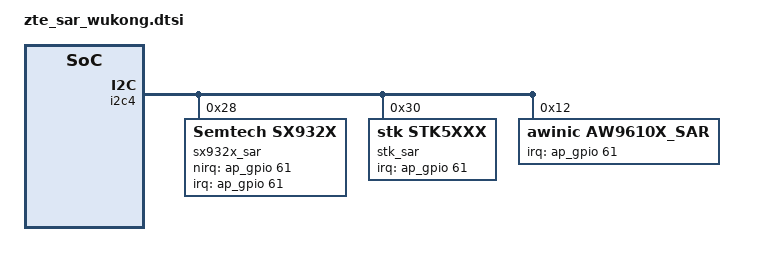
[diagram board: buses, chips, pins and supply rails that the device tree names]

&i2c4 {
	status = "okay";
	sx932x_sar:sar@28 {
		compatible = "Semtech,sx932x";
		reg = <0x28>;
		interrupt-parent = <&ap_gpio>;
		interrupts = <61 0>;
		Semtech,nirq-gpio = <&ap_gpio 61 0>;
		status ="ok";
		Semtech,reg-num = <53>;
		Semtech,reg-init  = /bits/ 8 < 0x03 0x0f /*use for compensation*/
			0x05 0x60 /*irq config*/
			0x06 0x00
			0x07 0x80
			0x08 0x00
			0x10 0x16
			0x14 0x00
			0x15 0x00
			0x20 0x10 /**/
			0x21 0x10
			0x22 0x00
			0x23 0x01
			0x24 0x17
			0x25 0x00
			0x26 0x01
			0x27 0x17
			0x28 0x3D /*PH0: CS config CS2-GND,CS1-HZ,CS0-HZ */
			0x29 0x34 /*PH1: CS config CS2-GND,CS1-input,CS0-GND*/
			0x2A 0x1F /*PH2: CS config CS2-input,CS1-GND,CS0-GND*/
			0x2B 0x37 /*PH3: CS config CS2-GND,CS1-input,CS0-GND*/
			0x2C 0x12 /**/
			0x2D 0x06
			0x30 0x0A
			0x31 0x08
			0x32 0x20
			0x33 0x20
			0x34 0x0B
			0x35 0x1A
			0x36 0x20 /*PH0/1 threshold*/
			0x37 0x24 /*PH2/3 threshold*/
			0x40 0x00
			0x41 0x00
			0x42 0x00
			0x43 0x00
			0x44 0x00
			0x45 0x05
			0x46 0x00
			0x47 0x00
			0x48 0x00
			0x49 0x00
			0x4A 0x40
			0x4B 0x00
			0x4C 0x00
			0x4D 0x00
			0x4E 0x80
			0x4F 0x0C
			0x50 0x00
			0x51 0x00
			0x52 0x00
			0x53 0x00
			0x54 0x00
			0x60 0x01
			0x11 0x22>; /*PH select PH1*/
	};
	stk_sar:stk@30 {
		compatible = "stk,stk5xxx";
		reg = <0x30>;
		interrupt-parent = <&ap_gpio>;
		stk5xxx,irq-gpio = <&ap_gpio 61 0>;
		stk,direction = <1>;
	};
	aw9610x_sar@12 {
		compatible = "awinic,aw9610x_sar";
		reg = <0x12>;
		irq-gpio = <&ap_gpio 61 0>;
		chip_name = "AW96103";
		sar_scan_time = < 1000 >;
		status = "okay";
	};
};

